# PIC32MX764F128L device description
Architecture: MIPS; Family: PIC32MX; Series: PIC32MX
Registers are 32-bit, read-write, no defined reset value unless marked. A register's access mark holds for its fields unless they carry their own. Offsets are from the block's base; [hi:lo] are bit positions; 'fields as' and 'values as' point back to an identical list.

## BMX
Instances: BMX 0x1f882000 in periph2
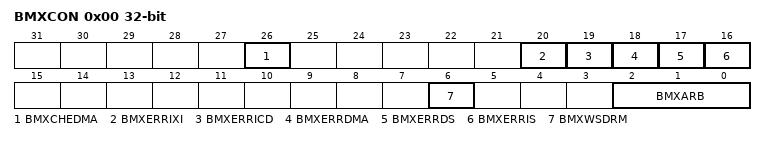
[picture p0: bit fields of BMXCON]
0x00 BMXCON — Bus Matrix Configuration Register
  [26] BMXCHEDMA — BMX PFM Cacheability for DMA Accesses bit
    1=Enable program Flash memory (data) cacheability for DMA accesses (requires cache to have data caching enabled); 0=Disable program Flash memory (data) cacheability for DMA accesses(hits are still read from the cache
  [20] BMXERRIXI — Enable Bus Error from IXI bit
    1=Enable bus error exceptions for unmapped address accesses initiated from IXI shared bus; 0=Disable bus error exceptions for unmapped address accesses initiated from IXI shared bus
  [19] BMXERRICD — Enable Bus Error from ICD Debug Unit bit
    1=Enable bus error exceptions for unmapped address accesses initiated from ICD; 0=Disable bus error exceptions for unmapped address accesses initiated from ICD
  [18] BMXERRDMA — Bus Error from DMA bit
    1=Enable bus error exceptions for unmapped address accesses initiated from DMA; 0=Disable bus error exceptions for unmapped address accesses initiated from DMA
  [17] BMXERRDS — Bus Error from CPU Data Access bit
    1=Enable bus error exceptions for unmapped address accesses initiated from CPU data access; 0=Disable bus error exceptions for unmapped address accesses initiated from CPU data access
  [16] BMXERRIS — Bus Error from CPU Instruction Access bit
    1=Enable bus error exceptions for unmapped address accesses initiated from CPU instruction access; 0=Disable bus error exceptions for unmapped address accesses initiated from CPU instruction access
  [6] BMXWSDRM — CPU Instruction or Data Access from Data RAM Wait State bit
    1=Data RAM accesses from CPU have one wait state for address setup; 0=Data RAM accesses from CPU have zero wait states for address setup
  [2:0] BMXARB — Bus Matrix Arbitration Mode bits
    2=Arbitration Mode 2; 1=Arbitration Mode 1 (default); 0=Arbitration Mode 0
0x10 BMXDKPBA — Data RAM Kernel Program Base Address Register
  [31:0] BMXDKPBA — DRM Kernel Program Base Address bits (bits 15-10, bits 9-0 are read only)
    0=No relative base address set
0x20 BMXDUDBA — Data RAM User Data Base Address Register
  [31:0] BMXDUDBA — DRM User Data Base Address bits (bits 15-10, bits 9-0 are read only)
    0=No relative base address set
0x30 BMXDUPBA — Data RAM User Program Base Address Register
  [31:0] BMXDUPBA — DRM User Program Base Address bits (bits 15-10, bits 9-0 are read only)
    0=No relative base address set
0x40 BMXDRMSZ ro — Data RAM Size Register
  [31:0] BMXDRMSZ — Data RAM Memory Size bits
    0x4000=Device has 16 KB RAM; 0x8000=Device has 32 KB RAM; 0x10000=Device has 64 KB RAM; 0x20000=Device has 128 KB RAM
0x50 BMXPUPBA — Program Flash (PFM) User Program Base Address Register
0x60 BMXPFMSZ ro — Program Flash (PFM) Size Register
  [31:0] BMXPFMSZ — Program Flash Memory (PFM) Size bits
    0x10000=Device has 64 KB Flash; 0x20000=Device has 128 KB Flash; 0x40000=Device has 256 KB Flash; 0x80000=Device has 512 KB Flash
0x70 BMXBOOTSZ ro — Boot Flash (IFM) Size Register
  [31:0] BMXBOOTSZ — Boot Flash Memory Size bits
    0x3000=Device has 12 KB Boot Flash

## CFG
Instances: CFG 0x1f80f200 in periph1
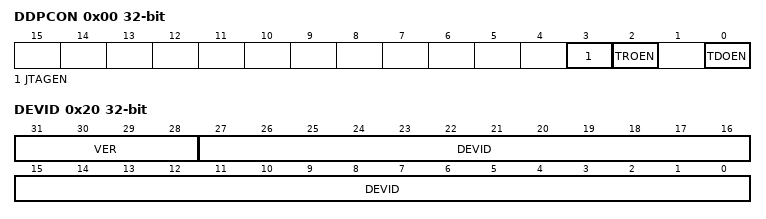
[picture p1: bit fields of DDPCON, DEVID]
0x00 DDPCON
  [3] JTAGEN — JTAG Port Enable bit
    1=Enable the JTAG port; 0=Disable the JTAG port
  [2] TROEN — Trace Output Enable bit
    1=Enable trace outputs and start trace clock (trace probe must be present); 0=Disable trace outputs and stop trace clock
  [0] TDOEN — TDO Enable for 2-Wire JTAG
    1=2-wire JTAG protocol uses TDO; 0=2-wire JTAG protocol does not use TDO
0x20 DEVID ro
  [31:28] VER, [27:0] DEVID
0x30 SYSKEY ro

## CMP
Instances: CMP 0x1f809ff4 in periph0
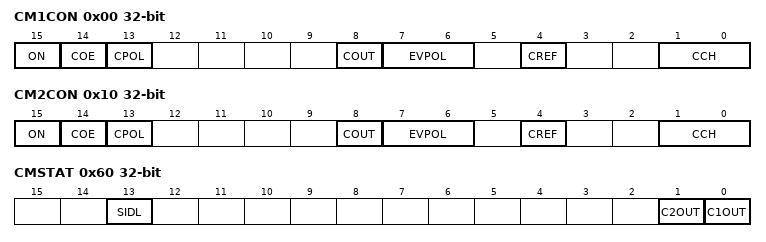
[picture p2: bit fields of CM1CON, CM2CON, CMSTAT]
0x00 CM1CON — Comparator Control Register
  [15] ON — Comparator ON bit
    1=Module is enabled. Setting this bit does not affect the other bits in this register; 0=Module is disabled and does not consume current. Clearing this bit does not affect the other bits in this register
  [14] COE — Comparator Output Enable bit
    1=Comparator output is driven on the output CxOUT pin; 0=Comparator output is not driven on the output CxOUT pin
  [13] CPOL — Comparator Output Inversion bit
    1=Output is inverted; 0=Output is not inverted
  [8] COUT — Comparator Output bit
    1=Output of the Comparator is a 1; 0=Output of the Comparator is a 0
  [7:6] EVPOL — Interrupt Event Polarity Select bits
    3=Comparator interrupt is generated on a low-to-high or high-to-low transition of the comparator output; 2=Comparator interrupt is generated on a high-to-low transition of the comparator output; 1=Comparator interrupt is generated on a low-to-high transition of the comparator output; 0=Comparator interrupt generation is disabled
  [4] CREF — Comparator Positive Input Configure bit
    1=Comparator non-inverting input is connected to the internal CVREF; 0=Comparator non-inverting input is connected to the C1IN+ pin
  [1:0] CCH — Comparator Negative Input Select bits for Comparator
    3=Comparator inverting input is connected to the IVREF; 2=Comparator inverting input is connected to the C2IN+ pin; 1=Comparator inverting input is connected to the C1IN+ pin; 0=Comparator inverting input is connected to the C1IN- pin
0x10 CM2CON — Comparator Control Register
  [15] ON — Comparator ON bit
    values as CM1CON.ON
  [14] COE — Comparator Output Enable bit
    values as CM1CON.COE
  [13] CPOL — Comparator Output Inversion bit
    1=Output is inverted; 0=Output is not inverted
  [8] COUT — Comparator Output bit
    values as CM1CON.COUT
  [7:6] EVPOL — Interrupt Event Polarity Select bits
    values as CM1CON.EVPOL
  [4] CREF — Comparator Positive Input Configure bit
    1=Comparator non-inverting input is connected to the internal CVREF; 0=Comparator non-inverting input is connected to the C2IN+ pin
  [1:0] CCH — Comparator Negative Input Select bits for Comparator
    3=Comparator inverting input is connected to the IVREF; 2=Comparator inverting input is connected to the C1IN+ pin; 1=Comparator inverting input is connected to the C2IN+ pin; 0=Comparator inverting input is connected to the C2IN- pin
0x60 CMSTAT — Comparator Status Register
  [13] SIDL — Stop in Idle Control bit
    1=All Comparator modules are disabled in Idle mode; 0=All Comparator modules continue to operate in the Idle mode
  [1] C2OUT — Comparator Output bit
    1=Output of Comparator 2 is a 1; 0=Output of Comparator 2 is a 0
  [0] C1OUT — Comparator Output bit
    1=Output of Comparator 1 is a 1; 0=Output of Comparator 1 is a 0

## Notices in the file
Copyright (c) 2019 Microchip Technology Inc.
SPDX-License-Identifier: Apache-2.0
Licensed under the Apache License, Version 2.0 (the "License");
you may not use this file except in compliance with the License.
You may obtain a copy of the License at
http://www.apache.org/licenses/LICENSE-2.0
Unless required by applicable law or agreed to in writing, software
distributed under the License is distributed on an "AS IS" BASIS,
WITHOUT WARRANTIES OR CONDITIONS OF ANY KIND, either express or implied.
See the License for the specific language governing permissions and
limitations under the License.
